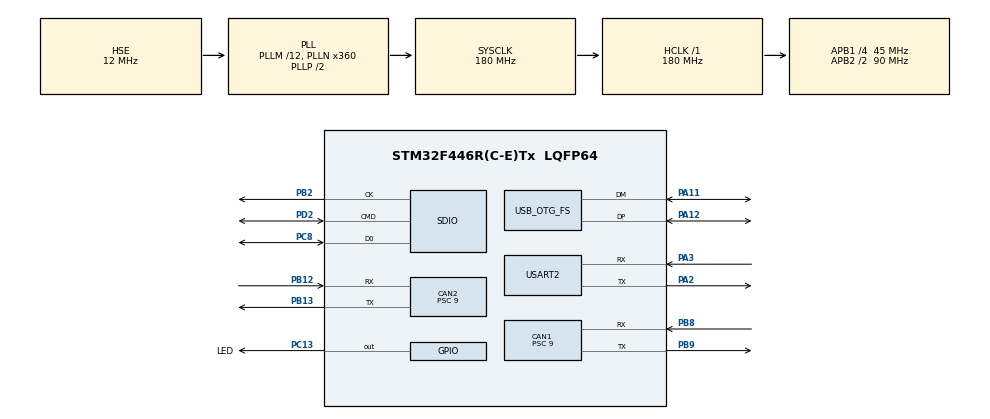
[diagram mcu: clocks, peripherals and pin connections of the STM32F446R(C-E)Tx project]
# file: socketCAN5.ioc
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CAN1.BS1=CAN_BS1_2TQ
CAN1.BS2=CAN_BS2_2TQ
CAN1.CalculateBaudRate=1000000
CAN1.CalculateTimeBit=1000
CAN1.CalculateTimeQuantum=200.0
CAN1.Prescaler=9
CAN2.BS1=CAN_BS1_2TQ
CAN2.BS2=CAN_BS2_2TQ
CAN2.CalculateBaudRate=1000000
CAN2.CalculateTimeBit=1000
CAN2.CalculateTimeQuantum=200.0
CAN2.Prescaler=9
Dma.Request0=USART2_RX
Dma.Request1=USART2_TX
Dma.Request2=SDIO
Dma.SDIO.2.Direction=DMA_PERIPH_TO_MEMORY
Dma.SDIO.2.FIFOMode=DMA_FIFOMODE_ENABLE
Dma.SDIO.2.FIFOThreshold=DMA_FIFO_THRESHOLD_FULL
Dma.SDIO.2.Instance=DMA2_Stream3
Dma.SDIO.2.MemBurst=DMA_MBURST_INC4
Dma.SDIO.2.MemDataAlignment=DMA_MDATAALIGN_WORD
Dma.SDIO.2.MemInc=DMA_MINC_ENABLE
Dma.SDIO.2.Mode=DMA_PFCTRL
Dma.SDIO.2.PeriphBurst=DMA_PBURST_INC4
Dma.SDIO.2.PeriphDataAlignment=DMA_PDATAALIGN_WORD
Dma.SDIO.2.PeriphInc=DMA_PINC_DISABLE
Dma.SDIO.2.Priority=DMA_PRIORITY_MEDIUM
Dma.USART2_RX.0.Direction=DMA_PERIPH_TO_MEMORY
Dma.USART2_RX.0.FIFOMode=DMA_FIFOMODE_DISABLE
Dma.USART2_RX.0.Instance=DMA1_Stream5
Dma.USART2_RX.0.MemDataAlignment=DMA_MDATAALIGN_BYTE
Dma.USART2_RX.0.MemInc=DMA_MINC_ENABLE
Dma.USART2_RX.0.Mode=DMA_CIRCULAR
Dma.USART2_RX.0.PeriphDataAlignment=DMA_PDATAALIGN_BYTE
Dma.USART2_RX.0.PeriphInc=DMA_PINC_DISABLE
Dma.USART2_RX.0.Priority=DMA_PRIORITY_MEDIUM
Dma.USART2_TX.1.Direction=DMA_MEMORY_TO_PERIPH
Dma.USART2_TX.1.FIFOMode=DMA_FIFOMODE_DISABLE
Dma.USART2_TX.1.Instance=DMA1_Stream6
Dma.USART2_TX.1.MemDataAlignment=DMA_MDATAALIGN_BYTE
Dma.USART2_TX.1.MemInc=DMA_MINC_ENABLE
Dma.USART2_TX.1.Mode=DMA_CIRCULAR
Dma.USART2_TX.1.PeriphDataAlignment=DMA_PDATAALIGN_BYTE
Dma.USART2_TX.1.PeriphInc=DMA_PINC_DISABLE
Dma.USART2_TX.1.Priority=DMA_PRIORITY_MEDIUM
Mcu.Family=STM32F4
Mcu.Name=STM32F446R(C-E)Tx
Mcu.Package=LQFP64
NVIC.CAN1_RX0_IRQn=true\:0\:0\:false\:false\:true\:true\:true\:true
NVIC.CAN1_RX1_IRQn=true\:0\:0\:false\:false\:true\:true\:true\:true
NVIC.CAN2_RX0_IRQn=true\:0\:0\:false\:false\:true\:true\:true\:true
NVIC.CAN2_RX1_IRQn=true\:0\:0\:false\:false\:true\:true\:true\:true
NVIC.DMA1_Stream5_IRQn=true\:0\:0\:false\:false\:true\:false\:true\:true
NVIC.DMA1_Stream6_IRQn=true\:0\:0\:false\:false\:true\:false\:true\:true
NVIC.DMA2_Stream3_IRQn=true\:0\:0\:false\:false\:true\:false\:true\:true
NVIC.OTG_FS_IRQn=true\:0\:0\:false\:false\:true\:false\:true\:true
NVIC.PriorityGroup=NVIC_PRIORITYGROUP_4
NVIC.SDIO_IRQn=true\:0\:0\:false\:false\:true\:true\:true\:true
NVIC.USART2_IRQn=true\:0\:0\:false\:false\:true\:true\:true\:true
PA11.Mode=Device_Only
PA11.Signal=USB_OTG_FS_DM
PA12.Mode=Device_Only
PA12.Signal=USB_OTG_FS_DP
PA13.Mode=Serial_Wire
PA13.Signal=SYS_JTMS-SWDIO
PA14.Mode=Serial_Wire
PA14.Signal=SYS_JTCK-SWCLK
PA2.Mode=Asynchronous
PA2.Signal=USART2_TX
PA3.Mode=Asynchronous
PA3.Signal=USART2_RX
PB12.Mode=CAN_Activate
PB12.Signal=CAN2_RX
PB13.Mode=CAN_Activate
PB13.Signal=CAN2_TX
PB2.GPIO_PuPd=GPIO_PULLUP
PB2.Mode=SD_1_bit
PB2.Signal=SDIO_CK
PB8.Mode=CAN_Activate
PB8.Signal=CAN1_RX
PB9.Mode=CAN_Activate
PB9.Signal=CAN1_TX
PC13.GPIO_Label=LED
PC13.Signal=GPIO_Output
PC8.GPIO_PuPd=GPIO_PULLUP
PC8.Mode=SD_1_bit
PC8.Signal=SDIO_D0
PD2.Mode=SD_1_bit
PD2.Signal=SDIO_CMD
PH0-OSC_IN.Mode=HSE-External-Oscillator
PH0-OSC_IN.Signal=RCC_OSC_IN
PH1-OSC_OUT.Mode=HSE-External-Oscillator
PH1-OSC_OUT.Signal=RCC_OSC_OUT
ProjectManager.HeapSize=0x200
ProjectManager.StackSize=0x400
ProjectManager.TargetToolchain=STM32CubeIDE
RCC.AHBFreq_Value=180000000
RCC.APB1CLKDivider=RCC_HCLK_DIV4
RCC.APB1Freq_Value=45000000
RCC.APB1TimFreq_Value=90000000
RCC.APB2CLKDivider=RCC_HCLK_DIV2
RCC.APB2Freq_Value=90000000
RCC.APB2TimFreq_Value=180000000
RCC.CortexFreq_Value=180000000
RCC.HCLKFreq_Value=180000000
RCC.HSE_VALUE=12000000
RCC.PLLM=12
RCC.PLLN=360
RCC.PLLSAIM=12
RCC.PLLSAIP=RCC_PLLSAIP_DIV4
RCC.SYSCLKFreq_VALUE=180000000
RCC.SYSCLKSource=RCC_SYSCLKSOURCE_PLLCLK
RCC.USBCLockSelection=RCC_CLK48CLKSOURCE_PLLSAIP
RCC.USBFreq_Value=48000000
RCC.VCOOutputFreq_Value=360000000
SDIO.ClockDiv=8
SDIO.ClockEdge=SDIO_CLOCK_EDGE_RISING
USART2.VirtualMode=VM_ASYNC
USB_DEVICE.CLASS_NAME_FS=CUSTOM_HID
USB_DEVICE.VirtualMode-CUSTOM_HID_FS=CustomHid
USB_DEVICE.VirtualModeFS=Custom_Hid_FS
USB_OTG_FS.VirtualMode=Device_Only
VP_USB_DEVICE_VS_USB_DEVICE_CUSTOM_HID_FS.Mode=CUSTOM_HID_FS
board=custom

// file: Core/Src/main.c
#include "main.h"
#include "usb_device.h"

CAN_HandleTypeDef hcan1;
CAN_HandleTypeDef hcan2;

SD_HandleTypeDef hsd;
DMA_HandleTypeDef hdma_sdio;

UART_HandleTypeDef huart2;
DMA_HandleTypeDef hdma_usart2_rx;
DMA_HandleTypeDef hdma_usart2_tx;

void SystemClock_Config(void);
void PeriphCommonClock_Config(void);
static void MX_GPIO_Init(void);
static void MX_DMA_Init(void);
static void MX_CAN1_Init(void);
static void MX_CAN2_Init(void);
static void MX_SDIO_SD_Init(void);
static void MX_USART2_UART_Init(void);

int main(void)
{

  HAL_Init();

  SystemClock_Config();

  PeriphCommonClock_Config();

  MX_GPIO_Init();
  MX_DMA_Init();
  MX_CAN1_Init();
  MX_CAN2_Init();
  MX_USB_DEVICE_Init();
  MX_SDIO_SD_Init();
  MX_USART2_UART_Init();

  while (1)
  {

	  HAL_GPIO_TogglePin(LED_GPIO_Port, LED_Pin);
	  HAL_Delay(100);

  }

}

void SystemClock_Config(void)
{
  RCC_OscInitTypeDef RCC_OscInitStruct = {0};
  RCC_ClkInitTypeDef RCC_ClkInitStruct = {0};

  __HAL_RCC_PWR_CLK_ENABLE();
  __HAL_PWR_VOLTAGESCALING_CONFIG(PWR_REGULATOR_VOLTAGE_SCALE1);

  RCC_OscInitStruct.OscillatorType = RCC_OSCILLATORTYPE_HSE;
  RCC_OscInitStruct.HSEState = RCC_HSE_ON;
  RCC_OscInitStruct.PLL.PLLState = RCC_PLL_ON;
  RCC_OscInitStruct.PLL.PLLSource = RCC_PLLSOURCE_HSE;
  RCC_OscInitStruct.PLL.PLLM = 12;
  RCC_OscInitStruct.PLL.PLLN = 360;
  RCC_OscInitStruct.PLL.PLLP = RCC_PLLP_DIV2;
  RCC_OscInitStruct.PLL.PLLQ = 2;
  RCC_OscInitStruct.PLL.PLLR = 2;
  if (HAL_RCC_OscConfig(&RCC_OscInitStruct) != HAL_OK)
  {
    Error_Handler();
  }

  /** Activate the Over-Drive mode
  */
  if (HAL_PWREx_EnableOverDrive() != HAL_OK)
  {
    Error_Handler();
  }

  /** Initializes the CPU, AHB and APB buses clocks
  */
  RCC_ClkInitStruct.ClockType = RCC_CLOCKTYPE_HCLK|RCC_CLOCKTYPE_SYSCLK
                              |RCC_CLOCKTYPE_PCLK1|RCC_CLOCKTYPE_PCLK2;
  RCC_ClkInitStruct.SYSCLKSource = RCC_SYSCLKSOURCE_PLLCLK;
  RCC_ClkInitStruct.AHBCLKDivider = RCC_SYSCLK_DIV1;
  RCC_ClkInitStruct.APB1CLKDivider = RCC_HCLK_DIV4;
  RCC_ClkInitStruct.APB2CLKDivider = RCC_HCLK_DIV2;

  if (HAL_RCC_ClockConfig(&RCC_ClkInitStruct, FLASH_LATENCY_5) != HAL_OK)
  {
    Error_Handler();
  }
}

void PeriphCommonClock_Config(void)
{
  RCC_PeriphCLKInitTypeDef PeriphClkInitStruct = {0};

  /** Initializes the peripherals clock
  */
  PeriphClkInitStruct.PeriphClockSelection = RCC_PERIPHCLK_SDIO|RCC_PERIPHCLK_CLK48;
  PeriphClkInitStruct.PLLSAI.PLLSAIM = 12;
  PeriphClkInitStruct.PLLSAI.PLLSAIN = 192;
  PeriphClkInitStruct.PLLSAI.PLLSAIQ = 2;
  PeriphClkInitStruct.PLLSAI.PLLSAIP = RCC_PLLSAIP_DIV4;
  PeriphClkInitStruct.PLLSAIDivQ = 1;
  PeriphClkInitStruct.Clk48ClockSelection = RCC_CLK48CLKSOURCE_PLLSAIP;
  PeriphClkInitStruct.SdioClockSelection = RCC_SDIOCLKSOURCE_CLK48;
  if (HAL_RCCEx_PeriphCLKConfig(&PeriphClkInitStruct) != HAL_OK)
  {
    Error_Handler();
  }
}

static void MX_CAN1_Init(void)
{

  hcan1.Instance = CAN1;
  hcan1.Init.Prescaler = 9;
  hcan1.Init.Mode = CAN_MODE_NORMAL;
  hcan1.Init.SyncJumpWidth = CAN_SJW_1TQ;
  hcan1.Init.TimeSeg1 = CAN_BS1_2TQ;
  hcan1.Init.TimeSeg2 = CAN_BS2_2TQ;
  hcan1.Init.TimeTriggeredMode = DISABLE;
  hcan1.Init.AutoBusOff = DISABLE;
  hcan1.Init.AutoWakeUp = DISABLE;
  hcan1.Init.AutoRetransmission = DISABLE;
  hcan1.Init.ReceiveFifoLocked = DISABLE;
  hcan1.Init.TransmitFifoPriority = DISABLE;
  if (HAL_CAN_Init(&hcan1) != HAL_OK)
  {
    Error_Handler();
  }

}

static void MX_CAN2_Init(void)
{

  hcan2.Instance = CAN2;
  hcan2.Init.Prescaler = 9;
  hcan2.Init.Mode = CAN_MODE_NORMAL;
  hcan2.Init.SyncJumpWidth = CAN_SJW_1TQ;
  hcan2.Init.TimeSeg1 = CAN_BS1_2TQ;
  hcan2.Init.TimeSeg2 = CAN_BS2_2TQ;
  hcan2.Init.TimeTriggeredMode = DISABLE;
  hcan2.Init.AutoBusOff = DISABLE;
  hcan2.Init.AutoWakeUp = DISABLE;
  hcan2.Init.AutoRetransmission = DISABLE;
  hcan2.Init.ReceiveFifoLocked = DISABLE;
  hcan2.Init.TransmitFifoPriority = DISABLE;
  if (HAL_CAN_Init(&hcan2) != HAL_OK)
  {
    Error_Handler();
  }
  /* USER CODE BEGIN CAN2_Init 2 */
  HAL_CAN_ActivateNotification(&hcan2, CAN_IT_RX_FIFO0_MSG_PENDING);
  /* USER CODE END CAN2_Init 2 */

}

static void MX_SDIO_SD_Init(void)
{

  hsd.Instance = SDIO;
  hsd.Init.ClockEdge = SDIO_CLOCK_EDGE_RISING;
  hsd.Init.ClockBypass = SDIO_CLOCK_BYPASS_DISABLE;
  hsd.Init.ClockPowerSave = SDIO_CLOCK_POWER_SAVE_DISABLE;
  hsd.Init.BusWide = SDIO_BUS_WIDE_1B;
  hsd.Init.HardwareFlowControl = SDIO_HARDWARE_FLOW_CONTROL_DISABLE;
  hsd.Init.ClockDiv = 8;
  if (HAL_SD_Init(&hsd) != HAL_OK)
  {
    Error_Handler();
  }

}

static void MX_USART2_UART_Init(void)
{

  huart2.Instance = USART2;
  huart2.Init.BaudRate = 115200;
  huart2.Init.WordLength = UART_WORDLENGTH_8B;
  huart2.Init.StopBits = UART_STOPBITS_1;
  huart2.Init.Parity = UART_PARITY_NONE;
  huart2.Init.Mode = UART_MODE_TX_RX;
  huart2.Init.HwFlowCtl = UART_HWCONTROL_NONE;
  huart2.Init.OverSampling = UART_OVERSAMPLING_16;
  if (HAL_UART_Init(&huart2) != HAL_OK)
  {
    Error_Handler();
  }

}

static void MX_DMA_Init(void)
{

  /* DMA controller clock enable */
  __HAL_RCC_DMA1_CLK_ENABLE();
  __HAL_RCC_DMA2_CLK_ENABLE();

  /* DMA interrupt init */
  /* DMA1_Stream5_IRQn interrupt configuration */
  HAL_NVIC_SetPriority(DMA1_Stream5_IRQn, 0, 0);
  HAL_NVIC_EnableIRQ(DMA1_Stream5_IRQn);
  /* DMA1_Stream6_IRQn interrupt configuration */
  HAL_NVIC_SetPriority(DMA1_Stream6_IRQn, 0, 0);
  HAL_NVIC_EnableIRQ(DMA1_Stream6_IRQn);
  /* DMA2_Stream3_IRQn interrupt configuration */
  HAL_NVIC_SetPriority(DMA2_Stream3_IRQn, 0, 0);
  HAL_NVIC_EnableIRQ(DMA2_Stream3_IRQn);

}

static void MX_GPIO_Init(void)
{
  GPIO_InitTypeDef GPIO_InitStruct = {0};

  /* GPIO Ports Clock Enable */
  __HAL_RCC_GPIOC_CLK_ENABLE();
  __HAL_RCC_GPIOH_CLK_ENABLE();
  __HAL_RCC_GPIOA_CLK_ENABLE();
  __HAL_RCC_GPIOB_CLK_ENABLE();
  __HAL_RCC_GPIOD_CLK_ENABLE();

  /*Configure GPIO pin Output Level */
  HAL_GPIO_WritePin(LED_GPIO_Port, LED_Pin, GPIO_PIN_RESET);

  /*Configure GPIO pin : LED_Pin */
  GPIO_InitStruct.Pin = LED_Pin;
  GPIO_InitStruct.Mode = GPIO_MODE_OUTPUT_PP;
  GPIO_InitStruct.Pull = GPIO_NOPULL;
  GPIO_InitStruct.Speed = GPIO_SPEED_FREQ_LOW;
  HAL_GPIO_Init(LED_GPIO_Port, &GPIO_InitStruct);

}

void Error_Handler(void)
{
  __disable_irq();
  while (1)
  {
  }
}
